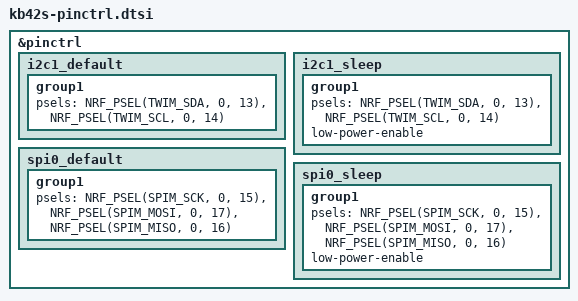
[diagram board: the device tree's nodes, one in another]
&pinctrl {
	i2c1_default: i2c1_default {
		group1 {
			psels = <NRF_PSEL(TWIM_SDA, 0, 13)>,
				<NRF_PSEL(TWIM_SCL, 0, 14)>;
		};
	};

	i2c1_sleep: i2c1_sleep {
		group1 {
			psels = <NRF_PSEL(TWIM_SDA, 0, 13)>,
				<NRF_PSEL(TWIM_SCL, 0, 14)>;
			low-power-enable;
		};
	};

	spi0_default: spi0_default {
		group1 {
			psels = <NRF_PSEL(SPIM_SCK, 0, 15)>,
				<NRF_PSEL(SPIM_MOSI, 0, 17)>,
				<NRF_PSEL(SPIM_MISO, 0, 16)>;
		};
	};

	spi0_sleep: spi0_sleep {
		group1 {
			psels = <NRF_PSEL(SPIM_SCK, 0, 15)>,
				<NRF_PSEL(SPIM_MOSI, 0, 17)>,
				<NRF_PSEL(SPIM_MISO, 0, 16)>;
			low-power-enable;
		};
	};
};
